# EFM32GG11B820F2048GL152 register map
File version: 4.0.0
CPU: CM4 r0p1, little endian, MPU, FPU, 3 interrupt priority bits
Registers are 32-bit, read-write, reset 0x0 unless marked. A register's access mark holds for its fields unless they carry their own. Offsets are from the block's base; [hi:lo] are bit positions; {n}, {i} and the like mark numbered series.

## LETIMER0
Base 0x40066000
Same registers: LETIMER1 0x40066400
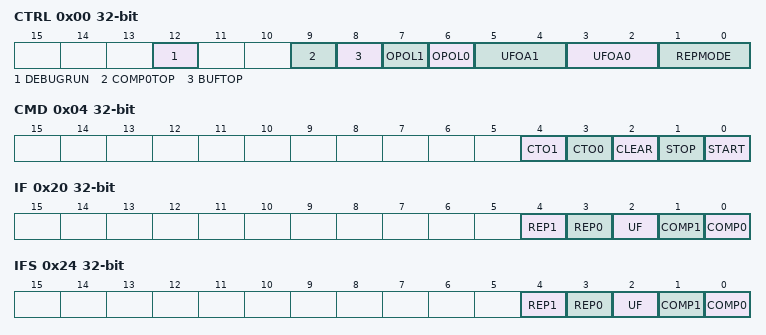
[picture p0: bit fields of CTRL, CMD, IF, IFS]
0x00 CTRL — Control Register
  [12] DEBUGRUN — Debug Mode Run Enable
  [9] COMP0TOP — Compare Value 0 is Top Value
  [8] BUFTOP — Buffered Top
  [7] OPOL1 — Output 1 Polarity
  [6] OPOL0 — Output 0 Polarity
  [5:4] UFOA1 — Underflow Output Action 1
    0=NONE (LETn_O1 is held at its idle value as defined by OPOL1); 1=TOGGLE (LETn_O1 is toggled on CNT underflow); 2=PULSE (LETn_O1 is held active for one LFACLKLETIMER0 clock cycle on CNT underflow. The output then returns to its idle value as defined by OPOL1); 3=PWM (LETn_O1 is set idle on CNT underflow, and active on compare match with COMP1)
  [3:2] UFOA0 — Underflow Output Action 0
    0=NONE (LETn_O0 is held at its idle value as defined by OPOL0); 1=TOGGLE (LETn_O0 is toggled on CNT underflow); 2=PULSE (LETn_O0 is held active for one LFACLKLETIMER0 clock cycle on CNT underflow. The output then returns to its idle value as defined by OPOL0); 3=PWM (LETn_O0 is set idle on CNT underflow, and active on compare match with COMP1)
  [1:0] REPMODE — Repeat Mode
    0=FREE (When started, the LETIMER counts down until it is stopped by software); 1=ONESHOT (The counter counts REP0 times. When REP0 reaches zero, the counter stops); 2=BUFFERED (The counter counts REP0 times. If REP1 has been written, it is loaded into REP0 when REP0 reaches zero, otherwise the counter stops); 3=DOUBLE (Both REP0 and REP1 are decremented when the LETIMER wraps around. The LETIMER counts until both REP0 and REP1 are zero)
0x04 CMD wo — Command Register
  [4] CTO1 — Clear Toggle Output 1
  [3] CTO0 — Clear Toggle Output 0
  [2] CLEAR — Clear LETIMER
  [1] STOP — Stop LETIMER
  [0] START — Start LETIMER
0x08 STATUS ro
  [0] RUNNING — LETIMER Running
0x0C CNT — Counter Value Register
  [15:0] CNT — Counter Value
0x10 COMP0 — Compare Value Register 0
  [15:0] COMP0 — Compare Value 0
0x14 COMP1 — Compare Value Register 1
  [15:0] COMP1 — Compare Value 1
0x18 REP0 — Repeat Counter Register 0
  [7:0] REP0 — Repeat Counter 0
0x1C REP1 — Repeat Counter Register 1
  [7:0] REP1 — Repeat Counter 1
0x20 IF ro — Interrupt Flag Register
  [4] REP1 — Repeat Counter 1 Interrupt Flag
  [3] REP0 — Repeat Counter 0 Interrupt Flag
  [2] UF — Underflow Interrupt Flag
  [1] COMP1 — Compare Match 1 Interrupt Flag
  [0] COMP0 — Compare Match 0 Interrupt Flag
0x24 IFS wo — Interrupt Flag Set Register
  [4] REP1 — Set REP1 Interrupt Flag
  [3] REP0 — Set REP0 Interrupt Flag
  [2] UF — Set UF Interrupt Flag
  [1] COMP1 — Set COMP1 Interrupt Flag
  [0] COMP0 — Set COMP0 Interrupt Flag
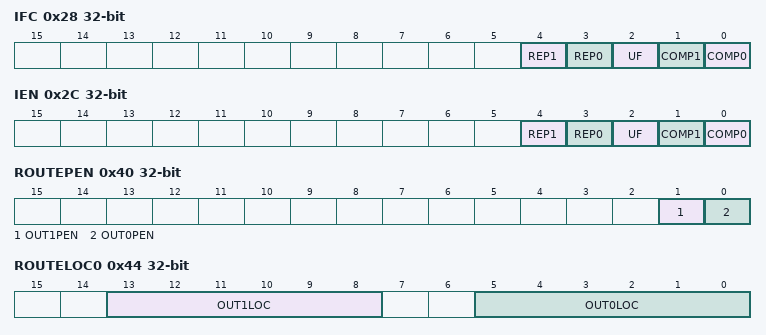
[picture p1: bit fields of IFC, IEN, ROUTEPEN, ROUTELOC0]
0x28 IFC wo — Interrupt Flag Clear Register
  [4] REP1 — Clear REP1 Interrupt Flag
  [3] REP0 — Clear REP0 Interrupt Flag
  [2] UF — Clear UF Interrupt Flag
  [1] COMP1 — Clear COMP1 Interrupt Flag
  [0] COMP0 — Clear COMP0 Interrupt Flag
0x2C IEN — Interrupt Enable Register
  [4] REP1 — REP1 Interrupt Enable
  [3] REP0 — REP0 Interrupt Enable
  [2] UF — UF Interrupt Enable
  [1] COMP1 — COMP1 Interrupt Enable
  [0] COMP0 — COMP0 Interrupt Enable
0x34 SYNCBUSY ro — Synchronization Busy Register
  [1] CMD — CMD Register Busy
0x40 ROUTEPEN — I/O Routing Pin Enable Register
  [1] OUT1PEN — Output 1 Pin Enable
  [0] OUT0PEN — Output 0 Pin Enable
0x44 ROUTELOC0 — I/O Routing Location Register
  [13:8] OUT1LOC — I/O Location
    {v}=LOC{v} (Location {v}) (v=0..7)
  [5:0] OUT0LOC — I/O Location
    {v}=LOC{v} (Location {v}) (v=0..7)
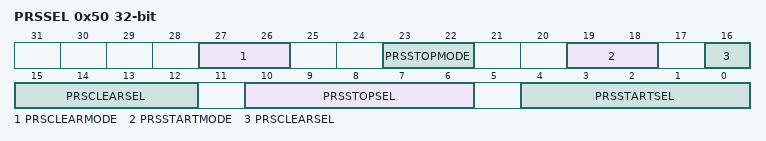
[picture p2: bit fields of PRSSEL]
0x50 PRSSEL — PRS Input Select Register
  [27:26] PRSCLEARMODE
    0=NONE (PRS cannot clear the LETIMER); 1=RISING (Rising edge of selected PRS input can clear the LETIMER); 2=FALLING (Falling edge of selected PRS input can clear the LETIMER); 3=BOTH (Both the rising or falling edge of the selected PRS input can clear the LETIMER)
  [23:22] PRSSTOPMODE
    0=NONE (PRS cannot stop the LETIMER); 1=RISING (Rising edge of selected PRS input can stop the LETIMER); 2=FALLING (Falling edge of selected PRS input can stop the LETIMER); 3=BOTH (Both the rising or falling edge of the selected PRS input can stop the LETIMER)
  [19:18] PRSSTARTMODE
    0=NONE (PRS cannot start the LETIMER); 1=RISING (Rising edge of selected PRS input can start the LETIMER); 2=FALLING (Falling edge of selected PRS input can start the LETIMER); 3=BOTH (Both the rising or falling edge of the selected PRS input can start the LETIMER)
  [16:12] PRSCLEARSEL — PRS Clear Select
    {v}=PRSCH{v} (PRS Channel {v} selected as input) (v=0..23)
  [10:6] PRSSTOPSEL — PRS Stop Select
    {v}=PRSCH{v} (PRS Channel {v} selected as input) (v=0..23)
  [4:0] PRSSTARTSEL — PRS Start Select
    {v}=PRSCH{v} (PRS Channel {v} selected as input) (v=0..23)

## Notices in the file
# License
Copyright 2021 Silicon Laboratories Inc. www.silabs.com
SPDX-License-Identifier: Zlib
The licensor of this software is Silicon Laboratories Inc.
This software is provided 'as-is', without any express or implied
warranty. In no event will the authors be held liable for any damages
arising from the use of this software.
Permission is granted to anyone to use this software for any purpose,
including commercial applications, and to alter it and redistribute it
freely, subject to the following restrictions:
1. The origin of this software must not be misrepresented; you must not
claim that you wrote the original software. If you use this software
in a product, an acknowledgment in the product documentation would be
appreciated but is not required.
2. Altered source versions must be plainly marked as such, and must not be
misrepresented as being the original software.
3. This notice may not be removed or altered from any source distribution.
